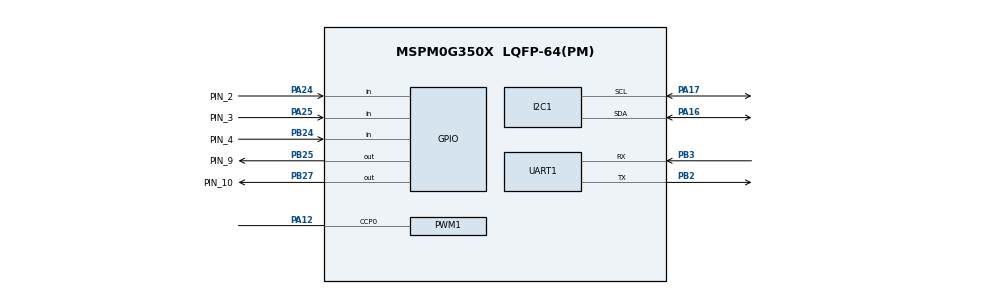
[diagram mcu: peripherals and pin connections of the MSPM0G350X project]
/**
 * @cliArgs --device "MSPM0G350X" --part "Default" --package "LQFP-64(PM)" --product "mspm0_sdk@2.11.00.07"
 * @versions {"tool":"1.26.2+4477"}
 */

/**
 * Import the modules used in this configuration.
 */
const GPIO   = scripting.addModule("/ti/driverlib/GPIO", {}, false);
const GPIO1  = GPIO.addInstance();
const GPIO2  = GPIO.addInstance();
const GPIO3  = GPIO.addInstance();
const GPIO4  = GPIO.addInstance();
const GPIO5  = GPIO.addInstance();
const GPIO6  = GPIO.addInstance();
const GPIO7  = GPIO.addInstance();
const GPIO8  = GPIO.addInstance();
const GPIO9  = GPIO.addInstance();
const GPIO10 = GPIO.addInstance();
const GPIO11 = GPIO.addInstance();
const I2C    = scripting.addModule("/ti/driverlib/I2C", {}, false);
const I2C1   = I2C.addInstance();
const PWM    = scripting.addModule("/ti/driverlib/PWM", {}, false);
const PWM1   = PWM.addInstance();
const SYSCTL = scripting.addModule("/ti/driverlib/SYSCTL");
const UART   = scripting.addModule("/ti/driverlib/UART", {}, false);
const UART1  = UART.addInstance();

/**
 * Write custom configuration values to the imported modules.
 */
const divider9       = system.clockTree["UDIV"];
divider9.divideValue = 2;

const multiplier2         = system.clockTree["PLL_QDIV"];
multiplier2.multiplyValue = 4;

const mux4       = system.clockTree["EXHFMUX"];
mux4.inputSelect = "EXHFMUX_XTAL";

const mux8       = system.clockTree["HSCLKMUX"];
mux8.inputSelect = "HSCLKMUX_SYSPLL0";

const mux12       = system.clockTree["SYSPLLMUX"];
mux12.inputSelect = "zSYSPLLMUX_HFCLK";

const pinFunction4       = system.clockTree["HFXT"];
pinFunction4.enable      = true;
pinFunction4.HFXTStartup = 10;
pinFunction4.inputFreq   = 40;

GPIO1.port                          = "PORTA";
GPIO1.$name                         = "GRAY_L2";
GPIO1.associatedPins[0].$name       = "PIN_0";
GPIO1.associatedPins[0].direction   = "INPUT";
GPIO1.associatedPins[0].assignedPin = "26";

const Board = scripting.addModule("/ti/driverlib/Board", {}, false);

GPIO2.port                          = "PORTA";
GPIO2.$name                         = "GRAY_L1";
GPIO2.associatedPins[0].$name       = "PIN_1";
GPIO2.associatedPins[0].assignedPin = "27";
GPIO2.associatedPins[0].direction   = "INPUT";

GPIO3.port                          = "PORTA";
GPIO3.$name                         = "GRAY_C";
GPIO3.associatedPins[0].$name       = "PIN_2";
GPIO3.associatedPins[0].direction   = "INPUT";
GPIO3.associatedPins[0].assignedPin = "24";
GPIO3.associatedPins[0].pin.$assign = "PA24";

GPIO4.$name                          = "GRAY_R1";
GPIO4.associatedPins[0].$name        = "PIN_3";
GPIO4.associatedPins[0].direction    = "INPUT";
GPIO4.associatedPins[0].assignedPort = "PORTA";
GPIO4.associatedPins[0].assignedPin  = "25";
GPIO4.associatedPins[0].pin.$assign  = "PA25";

GPIO5.$name                          = "GRAY_R2";
GPIO5.associatedPins[0].$name        = "PIN_4";
GPIO5.associatedPins[0].direction    = "INPUT";
GPIO5.associatedPins[0].assignedPort = "PORTB";
GPIO5.associatedPins[0].assignedPin  = "24";
GPIO5.associatedPins[0].pin.$assign  = "PB24";

GPIO6.$name                          = "MOTOR_AIN1";
GPIO6.associatedPins[0].$name        = "PIN_5";
GPIO6.associatedPins[0].assignedPort = "PORTB";
GPIO6.associatedPins[0].assignedPin  = "23";

GPIO7.$name                         = "MOTOR_AIN2";
GPIO7.associatedPins[0].$name       = "PIN_6";
GPIO7.associatedPins[0].assignedPin = "26";

GPIO8.$name                          = "MOTOR_BIN1";
GPIO8.associatedPins[0].$name        = "PIN_7";
GPIO8.associatedPins[0].assignedPort = "PORTB";
GPIO8.associatedPins[0].assignedPin  = "8";

GPIO9.$name                          = "MOTOR_BIN2";
GPIO9.associatedPins[0].$name        = "PIN_8";
GPIO9.associatedPins[0].assignedPort = "PORTB";
GPIO9.associatedPins[0].assignedPin  = "9";

GPIO10.$name                          = "BEEP";
GPIO10.associatedPins[0].$name        = "PIN_9";
GPIO10.associatedPins[0].initialValue = "SET";
GPIO10.associatedPins[0].pin.$assign  = "PB25";

GPIO11.$name                          = "STBY";
GPIO11.associatedPins[0].$name        = "PIN_10";
GPIO11.associatedPins[0].initialValue = "SET";
GPIO11.associatedPins[0].pin.$assign  = "PB27";

I2C1.$name                       = "I2C_0";
I2C1.basicEnableController       = true;
I2C1.basicTargetSecAddressEnable = true;
I2C1.advDigitalGlitchFilter      = "CLOCKS_1";
I2C1.enableDMAEvent1             = false;
I2C1.enableDMAEvent2             = false;
I2C1.peripheral.$assign          = "I2C1";
I2C1.peripheral.sdaPin.$assign   = "PA16";
I2C1.peripheral.sclPin.$assign   = "PA17";
I2C1.sdaPinConfig.$name          = "ti_driverlib_gpio_GPIOPinGeneric2";
I2C1.sclPinConfig.$name          = "ti_driverlib_gpio_GPIOPinGeneric3";

PWM1.$name                      = "PWM_0";
PWM1.peripheral.$assign         = "TIMG0";
PWM1.peripheral.ccp0Pin.$assign = "PA12";
PWM1.PWM_CHANNEL_0.$name        = "ti_driverlib_pwm_PWMTimerCC0";
PWM1.PWM_CHANNEL_0.dutyCycle    = 50;
PWM1.PWM_CHANNEL_0.ccValue      = 1000;
PWM1.PWM_CHANNEL_1.$name        = "ti_driverlib_pwm_PWMTimerCC1";
PWM1.PWM_CHANNEL_1.dutyCycle    = 50;
PWM1.PWM_CHANNEL_1.ccValue      = 1000;
PWM1.ccp0PinConfig.$name        = "ti_driverlib_gpio_GPIOPinGeneric0";
PWM1.ccp1PinConfig.$name        = "ti_driverlib_gpio_GPIOPinGeneric1";

SYSCTL.forceDefaultClkConfig = true;
SYSCTL.clockTreeEn           = true;
UART1.$name                            = "BT";
UART1.targetBaudRate                   = 9600;
UART1.enabledInterrupts                = [];
UART1.peripheral.$assign               = "UART3";
UART1.peripheral.rxPin.$assign         = "PB3";
UART1.peripheral.txPin.$assign         = "PB2";
UART1.txPinConfig.$name                = "ti_driverlib_gpio_GPIOPinGeneric4";
UART1.txPinConfig.direction            = scripting.forceWrite("OUTPUT");
UART1.txPinConfig.hideOutputInversion  = scripting.forceWrite(false);
UART1.txPinConfig.onlyInternalResistor = scripting.forceWrite(false);
UART1.txPinConfig.passedPeripheralType = scripting.forceWrite("Digital");
UART1.rxPinConfig.$name                = "ti_driverlib_gpio_GPIOPinGeneric5";
UART1.rxPinConfig.hideOutputInversion  = scripting.forceWrite(false);
UART1.rxPinConfig.onlyInternalResistor = scripting.forceWrite(false);
UART1.rxPinConfig.passedPeripheralType = scripting.forceWrite("Digital");

/**
 * Pinmux solution for unlocked pins/peripherals. This ensures that minor changes to the automatic solver in a future
 * version of the tool will not impact the pinmux you originally saw.  These lines can be completely deleted in order to
 * re-solve from scratch.
 */
pinFunction4.peripheral.$suggestSolution           = "SYSCTL";
pinFunction4.peripheral.hfxInPin.$suggestSolution  = "PA5";
pinFunction4.peripheral.hfxOutPin.$suggestSolution = "PA6";
GPIO1.associatedPins[0].pin.$suggestSolution       = "PA26";
Board.peripheral.$suggestSolution                  = "DEBUGSS";
Board.peripheral.swclkPin.$suggestSolution         = "PA20";
Board.peripheral.swdioPin.$suggestSolution         = "PA19";
GPIO2.associatedPins[0].pin.$suggestSolution       = "PA27";
GPIO6.associatedPins[0].pin.$suggestSolution       = "PB23";
GPIO7.associatedPins[0].pin.$suggestSolution       = "PB26";
GPIO8.associatedPins[0].pin.$suggestSolution       = "PB8";
GPIO9.associatedPins[0].pin.$suggestSolution       = "PB9";
PWM1.peripheral.ccp1Pin.$suggestSolution           = "PA13";
UART1.peripheral.$suggestSolution                  = "UART3";
